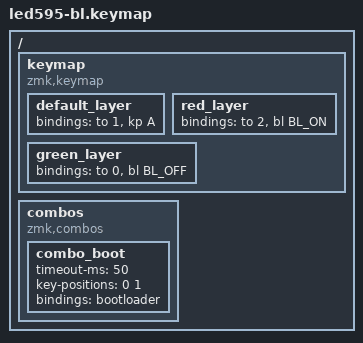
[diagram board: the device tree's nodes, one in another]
#include <behaviors.dtsi>
#include <dt-bindings/zmk/keys.h>
#include <dt-bindings/zmk/backlight.h>

/ {
  keymap {
    compatible = "zmk,keymap";
    default_layer {
      bindings = <&to 1 &kp A>;
    };
    red_layer {
      bindings = <&to 2 &bl BL_ON>;
    };
    green_layer {
      bindings = <&to 0 &bl BL_OFF>;
    };
  };

  combos {
    compatible = "zmk,combos";
    combo_boot { timeout-ms = <50>; key-positions = <0 1>; bindings = <&bootloader>; };
  };
};
